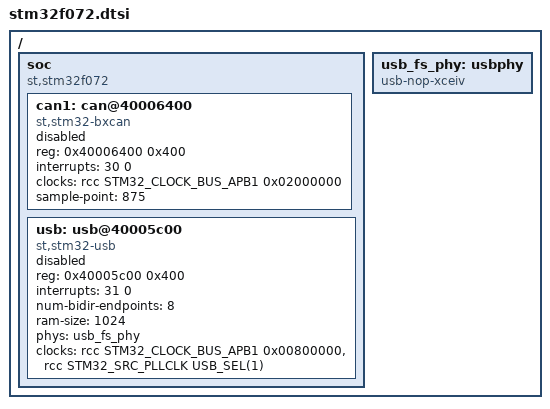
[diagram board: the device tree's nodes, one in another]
/*
 * Copyright (c) 2017 BayLibre, SAS
 *
 * SPDX-License-Identifier: Apache-2.0
 */

#include <st/f0/stm32f071.dtsi>

/ {
	soc {
		compatible = "st,stm32f072", "st,stm32f0", "simple-bus";

		can1: can@40006400 {
			compatible = "st,stm32-bxcan";
			reg = <0x40006400 0x400>;
			interrupts = <30 0>;
			clocks = <&rcc STM32_CLOCK_BUS_APB1 0x02000000>;
			status = "disabled";
			sample-point = <875>;
		};

		usb: usb@40005c00 {
			compatible = "st,stm32-usb";
			reg = <0x40005c00 0x400>;
			interrupts = <31 0>;
			interrupt-names = "usb";
			num-bidir-endpoints = <8>;
			ram-size = <1024>;
			phys = <&usb_fs_phy>;
			clocks = <&rcc STM32_CLOCK_BUS_APB1 0x00800000>,
				 <&rcc STM32_SRC_PLLCLK USB_SEL(1)>;
			status = "disabled";
		};
	};

	usb_fs_phy: usbphy {
		compatible = "usb-nop-xceiv";
		#phy-cells = <0>;
	};
};
